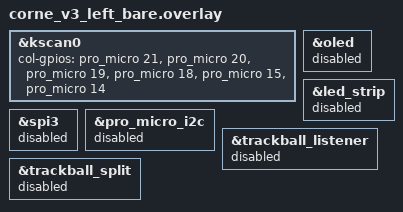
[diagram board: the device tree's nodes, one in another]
/*
 * Bare left overlay: disable OLED / RGB / pointing so bring-up cannot hang on I2C/SPI.
 */
#include "corne_v3.dtsi"

&kscan0 {
	col-gpios
		= <&pro_micro 21 GPIO_ACTIVE_HIGH>
		, <&pro_micro 20 GPIO_ACTIVE_HIGH>
		, <&pro_micro 19 GPIO_ACTIVE_HIGH>
		, <&pro_micro 18 GPIO_ACTIVE_HIGH>
		, <&pro_micro 15 GPIO_ACTIVE_HIGH>
		, <&pro_micro 14 GPIO_ACTIVE_HIGH>
		;
};

&oled {
	status = "disabled";
};

&led_strip {
	status = "disabled";
};

&spi3 {
	status = "disabled";
};

&pro_micro_i2c {
	status = "disabled";
};

&trackball_listener {
	status = "disabled";
};

&trackball_split {
	status = "disabled";
};
